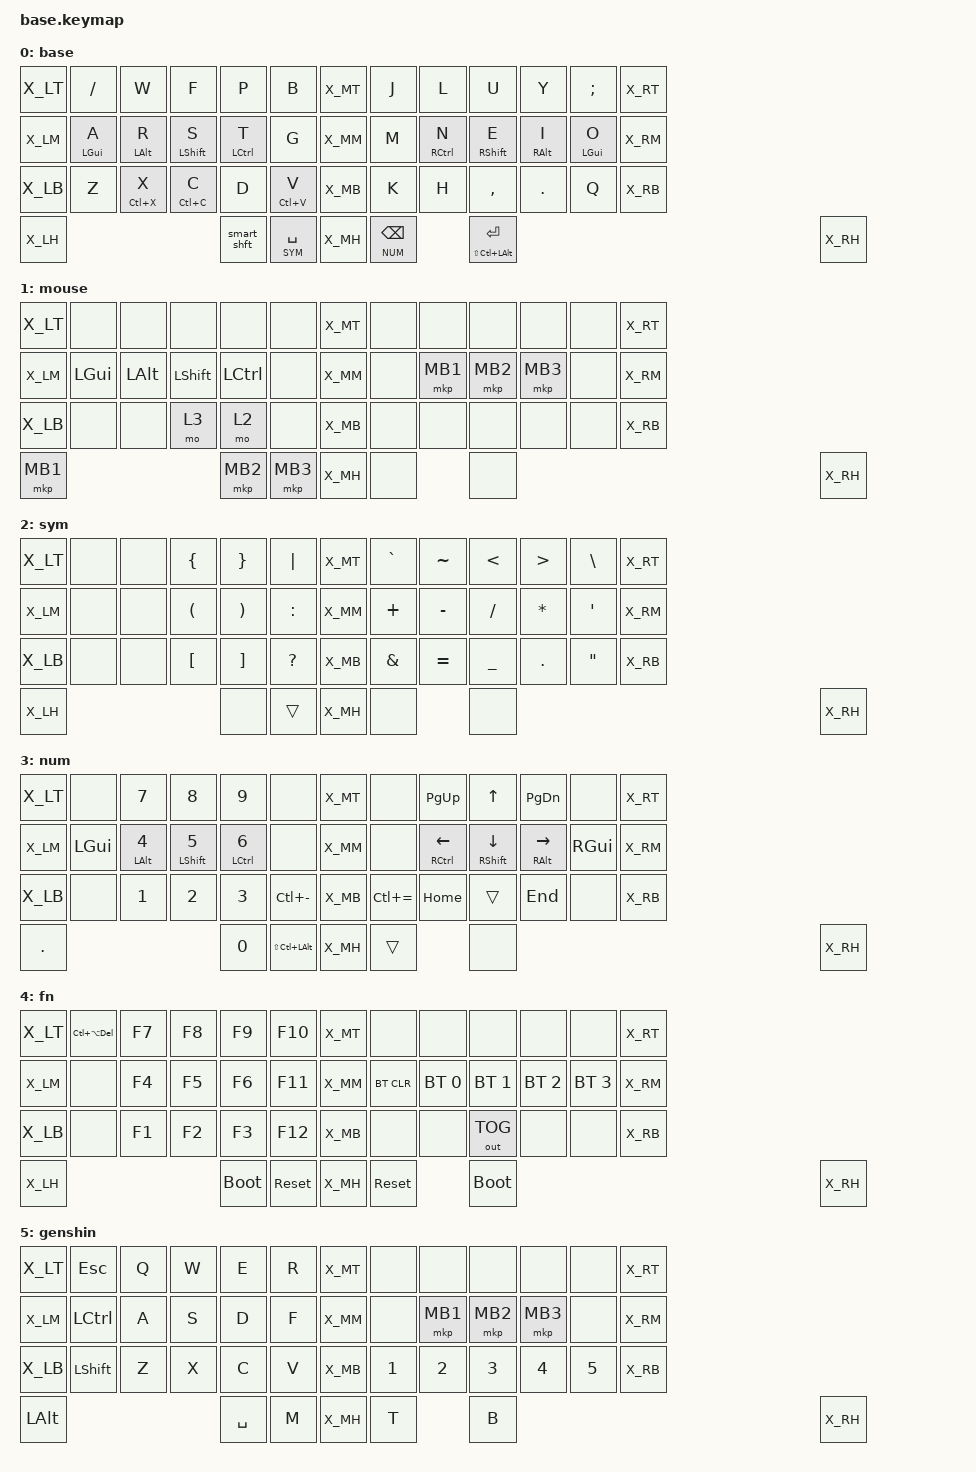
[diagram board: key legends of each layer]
#include <behaviors.dtsi>
#include <dt-bindings/zmk/keys.h>
#include <dt-bindings/zmk/bt.h>
#include <dt-bindings/zmk/ext_power.h>
#include <dt-bindings/zmk/outputs.h>
#include <dt-bindings/zmk/mouse.h>
#include <behaviors/mouse_keys.dtsi>

#include "../zmk-nodefree-config/helper.h"

#define DEF 0
#define MOUSE 1
#define SYM 2
#define NUM 3
#define FN 4
#define GENSHIN 5

#define XXX &none
#define ___ &trans

/* Global settings */

#define QUICK_TAP_MS 175
#include "conf_changes.dtsi"

#include "combos.dtsi"  // requires layer aliases
#include "extra_keys.h"
#include "behavior.dtsi"

/* Keymap */

ZMK_LAYER(base,
    X_LT     &kp FSLH       &kp W          &kp F           &kp P           &kp B             X_MT     &kp J      &kp L       &kp U      &kp Y    &kp SEMI      X_RT
    X_LM     &hml LGUI A    &hml LALT R    &hml LSHFT S    &hml LCTRL T    &kp G             X_MM     &kp M      &hmr RCTRL N                  &hmr RSHFT E             &hmr RALT I                 &hmr LGUI O   X_RM
    X_LB     &kp Z          &mt LC(X) X    &mt LC(C) C     &kp D           &mt LC(V) V       X_MB     &kp K                      &kp H                         &kp COMMA                &kp DOT                     &kp Q         X_RB
    X_LH                                                   &smart_shft     &lt SYM SPACE     X_MH     &lt NUM BACKSPACE          &mt LS(LC(LEFT_ALT)) ENTER                                                                       X_RH
)

ZMK_LAYER(mouse,
    X_LT     XXX      XXX      XXX       XXX       XXX       X_MT      XXX    XXX       XXX       XXX       XXX X_RT
    X_LM     &kp LGUI &kp LALT &kp LSHFT &kp LCTRL XXX       X_MM      XXX    &mkp MB1 &mkp MB2 &mkp MB3 XXX X_RM
    X_LB     XXX      XXX      &mo 3       &mo 2   XXX       X_MB      XXX    XXX       XXX       XXX       XXX X_RB
                               &mkp MB1 &mkp MB2 &mkp MB3 X_MH      XXX    XXX       X_RH
    )

ZMK_LAYER(sym,
    X_LT     XXX    XXX    &kp LEFT_BRACE          &kp RIGHT_BRACE          &kp PIPE         X_MT     &kp GRAVE    &kp TILDE    &kp LESS_THAN    &kp GREATER_THAN    &kp BACKSLASH         X_RT
    X_LM     XXX    XXX    &kp LEFT_PARENTHESIS    &kp RIGHT_PARENTHESIS    &kp COLON        X_MM     &kp PLUS     &kp MINUS    &kp SLASH        &kp ASTRK           &kp SINGLE_QUOTE      X_RM
    X_LB     XXX    XXX    &kp LEFT_BRACKET        &kp RIGHT_BRACKET        &kp QUESTION     X_MB     &kp AMPS     &kp EQUAL    &kp UNDER        &kp PERIOD          &kp DOUBLE_QUOTES     X_RB
    X_LH                                           XXX                      ___              X_MH     XXX          XXX                                                                     X_RH
)

ZMK_LAYER(num,
    X_LT     XXX        &kp N7          &kp N8           &kp N9           XXX                     X_MT     XXX              &kp PG_UP          &kp UP             &kp PG_DN          XXX          X_RT
    X_LM     &kp LGUI   &hml LALT N4    &hml LSHFT N5    &hml LCTRL N6    XXX                     X_MM     XXX              &hmr RCTRL LEFT    &hmr RSHFT DOWN    &hmr RALT RIGHT    &kp RGUI     X_RM
    X_LB     XXX        &kp N1          &kp N2           &kp N3           &kp LC(MINUS)           X_MB     &kp LC(EQUAL)    &kp HOME           ___                &kp END            XXX          X_RB
    &kp DOT                                              &kp N0           &kp LS(LC(LEFT_ALT))    X_MH     ___              XXX                                                                   X_RH
)

ZMK_LAYER(fn,
    X_LT     &kp LC(LA(DEL))    &kp F7    &kp F8    &kp F9         &kp F10        X_MT     XXX           XXX             XXX             XXX             XXX             X_RT
    X_LM     XXX                &kp F4    &kp F5    &kp F6         &kp F11        X_MM     &bt BT_CLR    &bt BT_SEL 0    &bt BT_SEL 1    &bt BT_SEL 2    &bt BT_SEL 3    X_RM
    X_LB     XXX                &kp F1    &kp F2    &kp F3         &kp F12        X_MB     XXX           XXX             &out OUT_TOG    XXX             XXX             X_RB
    X_LH                                            &bootloader    &sys_reset     X_MH     &sys_reset    &bootloader                                                     X_RH
)



ZMK_LAYER(genshin,
   X_LT &kp ESCAPE    &kp Q     &kp W     &kp E     &kp R       X_MT     XXX      XXX      XXX      XXX         XXX     X_RT
   X_LM &kp LCTRL     &kp A     &kp S     &kp D     &kp F       X_MM     XXX      &mkp MB1 &mkp MB2 &mkp MB3    XXX     X_RM
   X_LB &kp LSHIFT    &kp Z     &kp X     &kp C     &kp V       X_MB     &kp N1   &kp N2   &kp N3   &kp N4      &kp N5  X_RB
                               &kp LALT &kp SPACE    &kp M      X_MH     &kp T    &kp B                          X_RH
)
